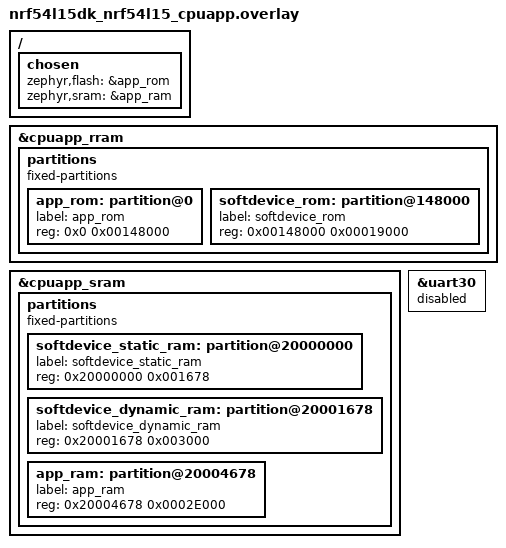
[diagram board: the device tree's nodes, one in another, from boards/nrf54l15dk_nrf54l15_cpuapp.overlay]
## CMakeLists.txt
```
#
# Copyright (c) 2025 Nordic Semiconductor ASA
#
# SPDX-License-Identifier: LicenseRef-Nordic-5-Clause
#

cmake_minimum_required(VERSION 3.20.0)

find_package(Zephyr REQUIRED HINTS $ENV{ZEPHYR_BASE})
project(ble_nus)

target_sources(app PRIVATE src/main.c)
```

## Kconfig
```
#
# Copyright (c) 2025 Nordic Semiconductor ASA
#
# SPDX-License-Identifier: LicenseRef-Nordic-5-Clause
#

menu "BLE NUS sample"

config BLE_UART_IRQ_PRIO
	int "BLE UART IRQ priority"
	default 3

config BLE_UART_PIN_TX
	int "BLE UART TX pin"
	default 6 if SOC_SERIES_NRF52X
	default 0

config BLE_UART_PIN_RX
	int "BLE UART RX pin"
	default 8 if SOC_SERIES_NRF52X
	default 1

config CONFIG_BLE_UART_PARITY
	bool "BLE UART use parity"

config BLE_UART_HWFC
	bool "BLE UART use HWFC"

if BLE_UART_HWFC

config BLE_UART_PIN_CTS
	int "BLE UART CTS pin"
	default 7 if SOC_SERIES_NRF52X
	default 3

config BLE_UART_PIN_RTS
	int "BLE UART RTS pin"
	default 5 if SOC_SERIES_NRF52X
	default 2

endif #BLE_UART_HWFC

endmenu # "BLE NUS sample"

module=BLE_NUS_SAMPLE
module-dep=LOG
module-str=BLE NUS Sample
source "${ZEPHYR_BASE}/subsys/logging/Kconfig.template.log_config"

source "Kconfig.zephyr"
```

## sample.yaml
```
sample:
  name: BLE Nordic UART service
tests:
  sample.ble_nus:
    build_only: true
    integration_platforms:
      - lite_nrf54l15/nrf54l15/cpuapp
    platform_allow:
      - lite_nrf54l15/nrf54l15/cpuapp
    tags: ci_build
  sample.ble_nus.no_logging:
    build_only: true
    integration_platforms:
      - lite_nrf52840/nrf52840
    platform_allow:
      - lite_nrf52840/nrf52840
    extra_args:
      - CONFIG_LITE_UARTE_CONSOLE=n
    tags: ci_build
```

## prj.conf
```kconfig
CONFIG_LOG=y
CONFIG_LOG_BACKEND_LITE_UARTE=y
CONFIG_CONSOLE=y
CONFIG_LITE_UARTE_CONSOLE=y

CONFIG_BLE_ADV=y
CONFIG_BLE_ADV_NAME="NCS-Lite NUS"
CONFIG_BLE_ADV_EXTENDED_ADVERTISING=n
CONFIG_BLE_ADV_DIRECTED_ADVERTISING=n

CONFIG_SOFTDEVICE=y

# BLE connection parameter
CONFIG_BLE_CONN_PARAMS=y

# Nordic UART service
CONFIG_BLE_NUS=y

# NUS depends on the Queued Writes module
CONFIG_NRF_BLE_QWR=y

# NUS requires storage of a vendor UUID
CONFIG_NRF_SDH_BLE_VS_UUID_COUNT=1
```

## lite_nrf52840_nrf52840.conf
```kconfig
CONFIG_LOG_BACKEND_LITE_UARTE=n
CONFIG_LITE_UARTE_CONSOLE=n
```

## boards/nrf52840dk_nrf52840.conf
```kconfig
CONFIG_NRFX_UARTE0=y

#Enable logging with RTT as UART is used for NUS service
CONFIG_LOG=y
CONFIG_USE_SEGGER_RTT=y
CONFIG_LOG_BACKEND_UART=n
CONFIG_LOG_BACKEND_RTT=y
CONFIG_LOG_MODE_IMMEDIATE=y
```

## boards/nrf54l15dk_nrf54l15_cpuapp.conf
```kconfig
CONFIG_NRFX_UARTE30=y

# These are enabled in zephyr by default on newer boards.
# Disable to let us pass pin configuration with the uarte config during init and let the uarte
# driver configure the pins.
CONFIG_NRFX_UARTE_CONFIG_SKIP_GPIO_CONFIG=n
CONFIG_NRFX_UARTE_CONFIG_SKIP_PSEL_CONFIG=n

CONFIG_LOG=y
CONFIG_LOG_BACKEND_UART=y
CONFIG_LOG_MODE_IMMEDIATE=y

#Enable logging with RTT instead of UART
#CONFIG_USE_SEGGER_RTT=y
#CONFIG_LOG_BACKEND_UART=n
#CONFIG_LOG_BACKEND_RTT=y
#CONFIG_LOG_MODE_IMMEDIATE=y
```

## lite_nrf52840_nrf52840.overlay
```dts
/* Needed until uart console PR merged */
&uart0 {
	status = "disabled";
};
```

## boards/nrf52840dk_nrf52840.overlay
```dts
&flash0 {
	partitions {
		compatible = "fixed-partitions";
		#address-cells = <1>;
		#size-cells = <1>;
		softdevice: partition@0 {
			label = "sd";
			reg = <0x00000000 0x00027000>;
		};
		app_rom: partition@27000 {
			label = "app";
			reg = <0x00027000 0x000d9000>;
		};
	};
};

&sram0 {
	reg = <0x20003400 DT_SIZE_K(200)>;
};

/* UART 0 */
&uart0 {
	status = "disabled";
};

/ {
	chosen {
		zephyr,flash = &app_rom;
		zephyr,sram = &sram0;
	};
};
```

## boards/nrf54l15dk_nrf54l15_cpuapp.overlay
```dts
/delete-node/ &boot_partition;
/delete-node/ &slot0_partition;
/delete-node/ &slot0_ns_partition;
/delete-node/ &slot1_partition;
/delete-node/ &slot1_ns_partition;
/delete-node/ &storage_partition;

&cpuapp_rram {
	partitions {
		compatible = "fixed-partitions";
		#address-cells = <1>;
		#size-cells = <1>;
		app_rom: partition@0 {
			label = "app_rom";
			reg = <0x0 0x00148000>;
		};
		softdevice_rom: partition@148000 {
			label = "softdevice_rom";
			reg = <0x00148000 0x00019000>;
		};
	};
};
&cpuapp_sram {
	partitions {
		compatible = "fixed-partitions";
		#address-cells = <1>;
		#size-cells = <1>;
		softdevice_static_ram: partition@20000000 {
			label = "softdevice_static_ram";
			reg = <0x20000000 0x001678>;
		};
		softdevice_dynamic_ram: partition@20001678 {
			label = "softdevice_dynamic_ram";
			reg = <0x20001678 0x003000>;
		};
		app_ram: partition@20004678 {
			label = "app_ram";
			reg = <0x20004678 0x0002E000>;
		};
	};
};

/* UART 30 */
&uart30 {
	status = "disabled";
};

/ {
	chosen {
		/delete-property/ zephyr,code-partition;
		zephyr,flash = &app_rom;
		zephyr,sram = &app_ram;
	};
};
```

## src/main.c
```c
/*
 * Copyright (c) 2025 Nordic Semiconductor ASA
 *
 * SPDX-License-Identifier: LicenseRef-Nordic-5-Clause
 */

#include <errno.h>
#include <string.h>
#include <nrf_sdh.h>
#include <nrf_sdh_ble.h>
#include <ble_adv.h>
#include <ble_conn_params.h>
#include <ble_gap.h>
#include <nrf_ble_qwr.h>
#include <bluetooth/services/ble_nus.h>
#include <nrf_soc.h>

#include <nrfx_uarte.h>
#include <zephyr/logging/log.h>
#include <zephyr/logging/log_ctrl.h>

LOG_MODULE_REGISTER(app, CONFIG_BLE_NUS_SAMPLE_LOG_LEVEL);

BLE_ADV_DEF(ble_adv); /* BLE advertising instance */
BLE_NUS_DEF(ble_nus); /* BLE NUS service instance */
NRF_BLE_QWR_DEF(ble_qwr); /* BLE QWR instance */

/** Handle of the current connection. */
static uint16_t conn_handle = BLE_CONN_HANDLE_INVALID;

/** NUS UARTE instance */
#if defined(CONFIG_SOC_SERIES_NRF52X)
static const nrfx_uarte_t uarte_inst = NRFX_UARTE_INSTANCE(0);
#elif defined(CONFIG_SOC_SERIES_NRF54LX)
static const nrfx_uarte_t uarte_inst = NRFX_UARTE_INSTANCE(30);
#endif

/* Maximum length of data (in bytes) that can be transmitted to the peer by the
 * Nordic UART service module.
 */
static volatile uint16_t ble_nus_max_data_len = BLE_NUS_MAX_DATA_LEN_CALC(BLE_GATT_ATT_MTU_DEFAULT);

static char uarte_rx_buf[10];

/**
 * @brief Handle data received from UART.
 *
 * @param[in] data Data received.
 * @param[in] data_len Size of data.
 */
static void uarte_rx_handler(char *data, size_t data_len)
{
	int err;
	uint8_t c;
	/* receive buffer used in UART ISR callback */
	static char rx_buf[BLE_NUS_MAX_DATA_LEN];
	static uint16_t rx_buf_idx;
	uint16_t len;

	for (int i = 0; i < data_len; i++) {
		c = data[i];

		if ((rx_buf_idx < sizeof(rx_buf)) && (c != '\n') && (c != '\r')) {
			rx_buf[rx_buf_idx++] = c;
		}

		if ((c == '\n' || c == '\r') || (rx_buf_idx >= ble_nus_max_data_len)) {
			if (rx_buf_idx == 0) {
				/* RX buffer is empty, nothing to send. */
				continue;
			}

			len = rx_buf_idx;
			LOG_INF("Sending data over BLE NUS, len %d", len);

			do {
				err = ble_nus_data_send(&ble_nus, rx_buf, &len, conn_handle);
				if ((err != 0) &&
				    (err != -EPIPE) &&
				    (err != -EAGAIN) &&
				    (err != -EBADF)) {
					LOG_ERR("Failed to send NUS data, err %d", err);
					return;
				}
			} while (err == -EAGAIN);

			if (len == rx_buf_idx) {
				rx_buf_idx = 0;
			} else {
				/* Not all data in RX buffer was transmitted.
				 * Move what is left to start of buffer.
				 */
				memmove(&rx_buf[len], &rx_buf[0], rx_buf_idx - len);
				rx_buf_idx -= len;
			}
		}
	}
}

/**
 * @brief UARTE event handler
 *
 * @param[in] event UARTE event structure
 * @param[in] ctx Context. NULL in this case.
 */
static void uarte_event_handler(nrfx_uarte_event_t const *event, void *ctx)
{
	switch (event->type) {
	case NRFX_UARTE_EVT_RX_DONE:
		LOG_DBG("Received data from UART: %c", event->data.rx.p_buffer[0]);
		if (event->data.rx.length > 0) {
			uarte_rx_handler(event->data.rx.p_buffer, event->data.rx.length);
		}

		/* Provide new UART RX buffer. */
		nrfx_uarte_rx(&uarte_inst, uarte_rx_buf, 1);
		break;
	case NRFX_UARTE_EVT_RX_BUF_REQUEST:
		nrfx_uarte_rx_buffer_set(&uarte_inst, uarte_rx_buf, 1);
		break;
	case NRFX_UARTE_EVT_ERROR:
		LOG_ERR("uarte error %#x", event->data.error.error_mask);
		break;
	default:
		break;
	}
}

/**
 * @brief BLE event handler.
 *
 * @param[in] evt BLE event.
 * @param[in] ctx Context.
 */
static void on_ble_evt(const ble_evt_t *evt, void *ctx)
{
	int err;

	switch (evt->header.evt_id) {
	case BLE_GAP_EVT_CONNECTED:
		LOG_INF("Peer connected");
		ble_nus_max_data_len = BLE_NUS_MAX_DATA_LEN_CALC(BLE_GATT_ATT_MTU_DEFAULT);
		conn_handle = evt->evt.gap_evt.conn_handle;
		err = sd_ble_gatts_sys_attr_set(conn_handle, NULL, 0, 0);
		if (err) {
			LOG_ERR("Failed to set system attributes, nrf_error %#x", err);
		}

		err = nrf_ble_qwr_conn_handle_assign(&ble_qwr, conn_handle);
		if (err) {
			LOG_ERR("Failed to assign qwr handle, err %d", err);
			return;
		}
		break;

	case BLE_GAP_EVT_DISCONNECTED:
		LOG_INF("Peer disconnected");
		if (conn_handle == evt->evt.gap_evt.conn_handle) {
			conn_handle = BLE_CONN_HANDLE_INVALID;
		}
		break;

	case BLE_GAP_EVT_AUTH_STATUS:
		LOG_INF("Authentication status: %#x",
			evt->evt.gap_evt.params.auth_status.auth_status);
		break;

	case BLE_GAP_EVT_SEC_PARAMS_REQUEST:
		/* Pairing not supported */
		err = sd_ble_gap_sec_params_reply(evt->evt.gap_evt.conn_handle,
						  BLE_GAP_SEC_STATUS_PAIRING_NOT_SUPP, NULL, NULL);
		if (err) {
			LOG_ERR("Failed to reply with Security params, nrf_error %#x", err);
		}
		break;

	case BLE_GATTS_EVT_SYS_ATTR_MISSING:
		LOG_INF("BLE_GATTS_EVT_SYS_ATTR_MISSING");
		/* No system attributes have been stored */
		err = sd_ble_gatts_sys_attr_set(conn_handle, NULL, 0, 0);
		if (err) {
			LOG_ERR("Failed to set system attributes, nrf_error %#x", err);
		}
		break;
	}
}
NRF_SDH_BLE_OBSERVER(sdh_ble, on_ble_evt, NULL, 0);

/**
 * @brief Connection parameters event handler
 *
 * @param[in] evt BLE connection parameters event.
 */
void on_conn_params_evt(const struct ble_conn_params_evt *evt)
{
	int err;

	switch (evt->id) {
	case BLE_CONN_PARAMS_EVT_REJECTED:
		err = sd_ble_gap_disconnect(evt->conn_handle, BLE_HCI_CONN_INTERVAL_UNACCEPTABLE);
		if (err) {
			LOG_ERR("Disconnect failed on conn params update rejection, nrf_error %#x",
				err);
		} else {
			LOG_INF("Disconnected from peer, unacceptable conn params");
		}
		break;

	case BLE_CONN_PARAMS_EVT_ATT_MTU_UPDATED:
		if (evt->conn_handle != conn_handle) {
			LOG_DBG("Connection handle does not match, expected %d, was %d",
				conn_handle, evt->conn_handle);
			break;
		}
		ble_nus_max_data_len = BLE_NUS_MAX_DATA_LEN_CALC(evt->att_mtu);
		LOG_INF("NUS max data length updated to %d", ble_nus_max_data_len);
		break;

	default:
		break;
	}
}

/**
 * @brief BLE advertising event handler
 *
 * @param[in] evt BLE advertising event type.
 */
static void ble_adv_evt_handler(enum ble_adv_evt evt)
{
	/* ignore */
}

static void ble_adv_error_handler(int error)
{
	LOG_ERR("Advertising error %d", error);
}

/**
 * @brief BLE NUS data handler
 *
 * @param[in] evt NUS event parameters.
 */
static void ble_nus_data_handler(struct ble_nus_evt *evt)
{
	const char newline = '\n';

	if (evt->type != BLE_NUS_EVT_RX_DATA) {
		return;
	}

	/* Handle incoming data */
	LOG_DBG("Received data from BLE NUS: %s", evt->params.rx_data.data);

	for (uint32_t i = 0; i < evt->params.rx_data.length; i++) {
		nrfx_uarte_tx(&uarte_inst, &evt->params.rx_data.data[i], 1, NRFX_UARTE_TX_BLOCKING);
	}

	if (evt->params.rx_data.data[evt->params.rx_data.length - 1] == '\r') {
		nrfx_uarte_tx(&uarte_inst, &newline, 1, NRFX_UARTE_TX_BLOCKING);
	}
}

/**
 * @brief Initalize UARTE driver.
 */
static int uarte_init(void)
{
	int err;

	nrfx_uarte_config_t uarte_config = NRFX_UARTE_DEFAULT_CONFIG(CONFIG_BLE_UART_PIN_TX,
								     CONFIG_BLE_UART_PIN_RX);

#if defined(CONFIG_BLE_UART_HWFC)
	uarte_config.config.hwfc = NRF_UARTE_HWFC_ENABLED;
	uarte_config.cts_pin = CONFIG_BLE_UART_PIN_CTS;
	uarte_config.rts_pin = CONFIG_BLE_UART_PIN_RTS;
#endif

#if defined(CONFIG_BLE_UART_PARITY)
	uarte_config.parity = NRF_UARTE_PARITY_INCLUDED;
#endif

	uarte_config.interrupt_priority = CONFIG_BLE_UART_IRQ_PRIO;

	/** We need to connect the IRQ ourselves. */
#if defined(CONFIG_SOC_SERIES_NRF52X)
	IRQ_CONNECT(NRFX_IRQ_NUMBER_GET(NRF_UARTE_INST_GET(0)), CONFIG_BLE_UART_IRQ_PRIO,
		    NRFX_UARTE_INST_HANDLER_GET(0), 0, 0);

		irq_enable(NRFX_IRQ_NUMBER_GET(NRF_UARTE_INST_GET(0)));
#elif defined(CONFIG_SOC_SERIES_NRF54LX)
	IRQ_CONNECT(NRFX_IRQ_NUMBER_GET(NRF_UARTE_INST_GET(30)), CONFIG_BLE_UART_IRQ_PRIO,
		    NRFX_UARTE_INST_HANDLER_GET(30), 0, 0);

	irq_enable(NRFX_IRQ_NUMBER_GET(NRF_UARTE_INST_GET(30)));
#endif

	err = nrfx_uarte_init(&uarte_inst, &uarte_config, uarte_event_handler);
	if (err != NRFX_SUCCESS) {
		LOG_ERR("Failed to initialize UART, nrfx err %d", err);
		return err;
	}

	/* optional: enable pull-up on RX pin in case pin may become floating.
	 * Induced noise on a floating RX input may lead to an UARTE error condition
	 */
#if defined(CONFIG_SOC_SERIES_NRF52X)
	NRF_GPIO->PIN_CNF[uarte_config.rxd_pin] |=
		(GPIO_PIN_CNF_PULL_Pullup << GPIO_PIN_CNF_PULL_Pos);
#endif

	return 0;
}

int main(void)
{
	int err;
	struct ble_adv_config ble_adv_cfg = {
		.conn_cfg_tag = CONFIG_NRF_SDH_BLE_CONN_TAG,
		.evt_handler = ble_adv_evt_handler,
		.error_handler = ble_adv_error_handler,
		.adv_data = {
			.name_type = BLE_ADV_DATA_FULL_NAME,
			.flags = BLE_GAP_ADV_FLAGS_LE_ONLY_GENERAL_DISC_MODE,
		},
	};

	struct ble_nus_config nus_cfg = {
		.data_handler = ble_nus_data_handler,
	};
	struct nrf_ble_qwr_init qwr_init_params = {0};

	LOG_INF("BLE NUS sample started");

	err = uarte_init();
	if (err) {
		LOG_ERR("Failed to enable UARTE, err %d", err);
		return -1;
	}

	err = nrf_sdh_enable_request();
	if (err) {
		LOG_ERR("Failed to enable SoftDevice, err %d", err);
		return -1;
	}

	LOG_INF("SoftDevice enabled");

	err = nrf_sdh_ble_enable(CONFIG_NRF_SDH_BLE_CONN_TAG);
	if (err) {
		LOG_ERR("Failed to enable BLE, err %d", err);
		return -1;
	}

	LOG_INF("Bluetooth enabled");

	err = nrf_ble_qwr_init(&ble_qwr, &qwr_init_params);
	if (err) {
		LOG_ERR("nrf_ble_qwr_init failed, err %d", err);
		return -1;
	}

	err = ble_nus_init(&ble_nus, &nus_cfg);
	if (err) {
		LOG_ERR("Failed to initialize Nordic uart service, err %d", err);
		return -1;
	}

	LOG_INF("Services initialized");

	err = ble_conn_params_event_handler_set(on_conn_params_evt);
	if (err) {
		LOG_ERR("Failed to setup conn param event handler, err %d", err);
		return -1;
	}

	err = ble_adv_init(&ble_adv, &ble_adv_cfg);
	if (err) {
		LOG_ERR("Failed to initialize advertising, err %d", err);
		return -1;
	}

	const uint8_t out[] = "UART started.\r\n";

	err = nrfx_uarte_tx(&uarte_inst, out, sizeof(out), NRFX_UARTE_TX_BLOCKING);
	if (err != NRFX_SUCCESS) {
		LOG_ERR("UARTE TX failed, nrfx err %d", err);
		return -1;
	}

	err = nrfx_uarte_rx(&uarte_inst, uarte_rx_buf, 1);
	if (err != NRFX_SUCCESS) {
		LOG_ERR("UART RX failed, nrfx err %d", err);
	}

	err = ble_adv_start(&ble_adv, BLE_ADV_MODE_FAST);
	if (err) {
		LOG_ERR("Failed to start advertising, err %d", err);
		return -1;
	}

	LOG_INF("Advertising as %s", CONFIG_BLE_ADV_NAME);
#if defined(CONFIG_SOC_SERIES_NRF54LX)
	LOG_INF("The NUS service is handled at a separate uart instance");
#endif

	while (true) {
		while (log_process()) {
			/* Empty. */
		}
		sd_app_evt_wait();
	}
}
```
